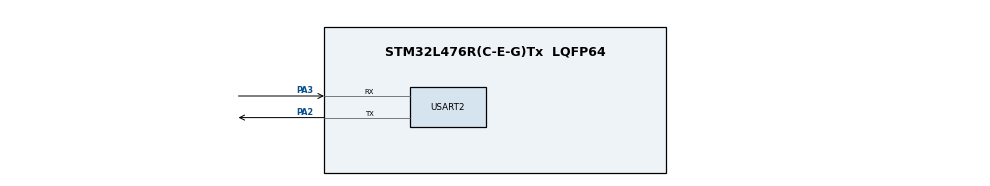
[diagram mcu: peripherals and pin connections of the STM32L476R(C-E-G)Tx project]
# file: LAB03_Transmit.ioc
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Mcu.Family=STM32L4
Mcu.Name=STM32L476R(C-E-G)Tx
Mcu.Package=LQFP64
NVIC.PriorityGroup=NVIC_PRIORITYGROUP_4
PA2.Mode=Asynchronous
PA2.Signal=USART2_TX
PA3.Mode=Asynchronous
PA3.Signal=USART2_RX
ProjectManager.HeapSize=0x200
ProjectManager.StackSize=0x400
ProjectManager.TargetToolchain=STM32CubeIDE
RCC.ADCFreq_Value=32000000
RCC.HSE_VALUE=8000000
RCC.HSI_VALUE=16000000
RCC.LSE_VALUE=32768
RCC.MSI_VALUE=4000000
RCC.PLLSAI1N=16
RCC.USBFreq_Value=32000000
RCC.VCOOutputFreq_Value=32000000
USART2.VirtualMode-Asynchronous=VM_ASYNC
VP_RNG_VS_RNG.Mode=RNG_Activate
board=custom

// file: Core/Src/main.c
/* USER CODE BEGIN Header */
/**
 * @file main.c
 * @brief UART transmit exercises.
 * @author Philipp Schilk, 2023
 */
/* USER CODE END Header */
#include "main.h"
#include <inttypes.h>
#include <stdint.h>
#include <stdio.h>

RNG_HandleTypeDef hrng;

UART_HandleTypeDef huart2;

void SystemClock_Config(void);
static void MX_GPIO_Init(void);
static void MX_USART2_UART_Init(void);
static void MX_RNG_Init(void);
/* USER CODE BEGIN PFP */
uint32_t generate_magic_number(void);
/* USER CODE END PFP */

int main(void) {

  /* MCU Configuration--------------------------------------------------------*/

  /* Reset of all peripherals, Initializes the Flash interface and the Systick. */
  HAL_Init();

  /* Configure the system clock */
  SystemClock_Config();

  /* Initialize all configured peripherals */
  MX_GPIO_Init();
  MX_USART2_UART_Init();
  MX_RNG_Init();

  /* Infinite loop */
  /* USER CODE BEGIN WHILE */
  const uint16_t DELAY = 2000;
  uint8_t buffer[16] = "Hello World\r\n";
  HAL_UART_Transmit(&huart2, (uint8_t *)buffer, 16, HAL_MAX_DELAY);
  HAL_Delay(DELAY);

  while (1) {

    // TODO: Send the string "Hello World!\r\n" via UART.
    uint32_t rng = 10;
    uint8_t r_char = (rng & 255) % (125 - 64) + 64;
    char buffer[] = "hello world\n";
    buffer[0] = (char)r_char & 0xff;
    HAL_UART_Transmit(&huart2, (uint8_t *)buffer, 16, HAL_MAX_DELAY);

    // printf("Hello World!\r\n");

    // TODO: After implementing the _write syscall, use printf to transmit
    //       The magic number generated by the generate_magic_number function.

    // printf("%" PRIu32 "\r\n", generate_magic_number());

    HAL_Delay(DELAY);

    /* USER CODE END WHILE */

  }
}

void SystemClock_Config(void) {
  RCC_OscInitTypeDef RCC_OscInitStruct = {0};
  RCC_ClkInitTypeDef RCC_ClkInitStruct = {0};

  /** Configure the main internal regulator output voltage
   */
  if (HAL_PWREx_ControlVoltageScaling(PWR_REGULATOR_VOLTAGE_SCALE1) != HAL_OK) {
    Error_Handler();
  }

  /** Initializes the RCC Oscillators according to the specified parameters
   * in the RCC_OscInitTypeDef structure.
   */
  RCC_OscInitStruct.OscillatorType = RCC_OSCILLATORTYPE_MSI;
  RCC_OscInitStruct.MSIState = RCC_MSI_ON;
  RCC_OscInitStruct.MSICalibrationValue = 0;
  RCC_OscInitStruct.MSIClockRange = RCC_MSIRANGE_6;
  RCC_OscInitStruct.PLL.PLLState = RCC_PLL_NONE;
  if (HAL_RCC_OscConfig(&RCC_OscInitStruct) != HAL_OK) {
    Error_Handler();
  }

  /** Initializes the CPU, AHB and APB buses clocks
   */
  RCC_ClkInitStruct.ClockType = RCC_CLOCKTYPE_HCLK | RCC_CLOCKTYPE_SYSCLK | RCC_CLOCKTYPE_PCLK1 | RCC_CLOCKTYPE_PCLK2;
  RCC_ClkInitStruct.SYSCLKSource = RCC_SYSCLKSOURCE_MSI;
  RCC_ClkInitStruct.AHBCLKDivider = RCC_SYSCLK_DIV1;
  RCC_ClkInitStruct.APB1CLKDivider = RCC_HCLK_DIV1;
  RCC_ClkInitStruct.APB2CLKDivider = RCC_HCLK_DIV1;

  if (HAL_RCC_ClockConfig(&RCC_ClkInitStruct, FLASH_LATENCY_0) != HAL_OK) {
    Error_Handler();
  }
}

static void MX_RNG_Init(void) {

  hrng.Instance = RNG;
  if (HAL_RNG_Init(&hrng) != HAL_OK) {
    Error_Handler();
  }
}

static void MX_USART2_UART_Init(void) {

  huart2.Instance = USART2;
  huart2.Init.BaudRate = 115200;
  huart2.Init.WordLength = UART_WORDLENGTH_8B;
  huart2.Init.StopBits = UART_STOPBITS_1;
  huart2.Init.Parity = UART_PARITY_NONE;
  huart2.Init.Mode = UART_MODE_TX_RX;
  huart2.Init.HwFlowCtl = UART_HWCONTROL_NONE;
  huart2.Init.OverSampling = UART_OVERSAMPLING_16;
  huart2.Init.OneBitSampling = UART_ONE_BIT_SAMPLE_DISABLE;
  huart2.AdvancedInit.AdvFeatureInit = UART_ADVFEATURE_NO_INIT;
  if (HAL_UART_Init(&huart2) != HAL_OK) {
    Error_Handler();
  }
}

static void MX_GPIO_Init(void) {

  /* GPIO Ports Clock Enable */
  __HAL_RCC_GPIOA_CLK_ENABLE();

}

/* USER CODE BEGIN 4 */

// TODO: Implement the _write syscall stub from syscalls.c to transmit the data
//       via UART.
// int _read(int file, char *ptr, int len) {
//   (void)file;
//   int DataIdx;

//   for (DataIdx = 0; DataIdx < len; DataIdx++) {
//     *ptr++ = __io_getchar();
//   }

//   return len;
// }

int _write(int file, char *ptr, int len) {
  (void)file;

  HAL_UART_Transmit(&huart2, (uint8_t *)ptr, len, 10 * len);
  return len;
}

uint32_t generate_magic_number(void) {
  uint32_t rng = HAL_RNG_GetRandomNumber(&hrng) & 268435455; // entropy
  uint32_t a = 255 & rng;                                    // ?
  uint32_t b = 2147483520 & (rng >> 1);                      // !
  return ((rng * 6) / (a + (b << 1))) * 7;                   // !!1!
}

/* USER CODE END 4 */

void Error_Handler(void) {
  __disable_irq();
  while (1) {
  }
}

#ifdef USE_FULL_ASSERT
/**
 * @brief  Reports the name of the source file and the source line number
 *         where the assert_param error has occurred.
 * @param  file: pointer to the source file name
 * @param  line: assert_param error line source number
 * @retval None
 */
void assert_failed(uint8_t *file, uint32_t line) {
  /* USER CODE BEGIN 6 */
  /* User can add his own implementation to report the file name and line
     number, ex: printf("Wrong parameters value: file %s on line %d\r\n", file,
     line) */
  /* USER CODE END 6 */
}
#endif /* USE_FULL_ASSERT */
